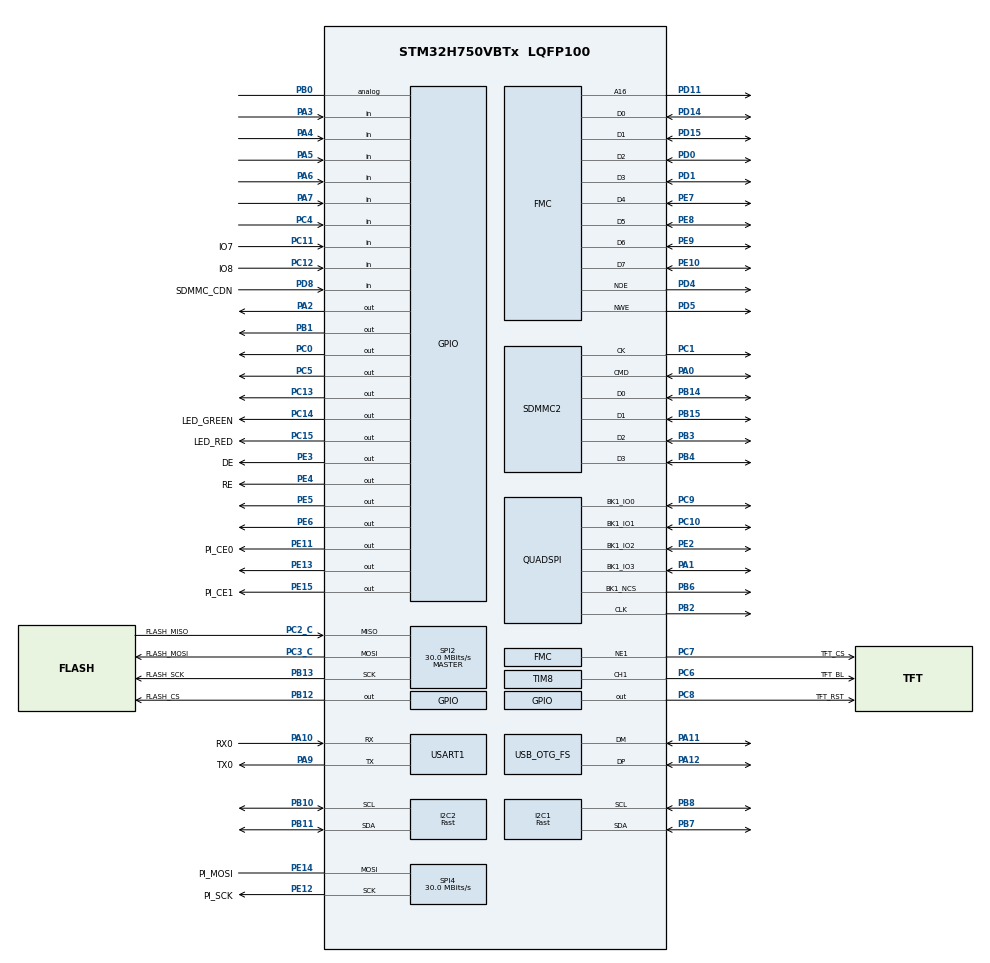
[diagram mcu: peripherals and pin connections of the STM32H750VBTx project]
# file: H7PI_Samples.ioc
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CORTEX_M7.AccessPermission-Cortex_Memory_Protection_Unit_Region0_Settings=MPU_REGION_FULL_ACCESS
CORTEX_M7.AccessPermission-Cortex_Memory_Protection_Unit_Region1_Settings=MPU_REGION_FULL_ACCESS
CORTEX_M7.AccessPermission-Cortex_Memory_Protection_Unit_Region2_Settings=MPU_REGION_FULL_ACCESS
CORTEX_M7.AccessPermission-Cortex_Memory_Protection_Unit_Region3_Settings=MPU_REGION_FULL_ACCESS
CORTEX_M7.AccessPermission-Cortex_Memory_Protection_Unit_Region4_Settings=MPU_REGION_FULL_ACCESS
CORTEX_M7.BaseAddress-Cortex_Memory_Protection_Unit_Region0_Settings=0x60000000
CORTEX_M7.BaseAddress-Cortex_Memory_Protection_Unit_Region1_Settings=0x24000000
CORTEX_M7.BaseAddress-Cortex_Memory_Protection_Unit_Region2_Settings=0x30000000
CORTEX_M7.BaseAddress-Cortex_Memory_Protection_Unit_Region3_Settings=0x38000000
CORTEX_M7.BaseAddress-Cortex_Memory_Protection_Unit_Region4_Settings=0x20000000
CORTEX_M7.CPU_DCache=Enabled
CORTEX_M7.CPU_ICache=Enabled
CORTEX_M7.Enable-Cortex_Memory_Protection_Unit_Region0_Settings=MPU_REGION_ENABLE
CORTEX_M7.Enable-Cortex_Memory_Protection_Unit_Region1_Settings=MPU_REGION_ENABLE
CORTEX_M7.Enable-Cortex_Memory_Protection_Unit_Region2_Settings=MPU_REGION_ENABLE
CORTEX_M7.Enable-Cortex_Memory_Protection_Unit_Region3_Settings=MPU_REGION_ENABLE
CORTEX_M7.Enable-Cortex_Memory_Protection_Unit_Region4_Settings=MPU_REGION_ENABLE
CORTEX_M7.IsBufferable-Cortex_Memory_Protection_Unit_Region0_Settings=MPU_ACCESS_BUFFERABLE
CORTEX_M7.IsBufferable-Cortex_Memory_Protection_Unit_Region1_Settings=MPU_ACCESS_BUFFERABLE
CORTEX_M7.IsBufferable-Cortex_Memory_Protection_Unit_Region2_Settings=MPU_ACCESS_BUFFERABLE
CORTEX_M7.IsBufferable-Cortex_Memory_Protection_Unit_Region3_Settings=MPU_ACCESS_BUFFERABLE
CORTEX_M7.IsBufferable-Cortex_Memory_Protection_Unit_Region4_Settings=MPU_ACCESS_BUFFERABLE
CORTEX_M7.IsCacheable-Cortex_Memory_Protection_Unit_Region1_Settings=MPU_ACCESS_CACHEABLE
CORTEX_M7.IsCacheable-Cortex_Memory_Protection_Unit_Region2_Settings=MPU_ACCESS_CACHEABLE
CORTEX_M7.IsCacheable-Cortex_Memory_Protection_Unit_Region3_Settings=MPU_ACCESS_CACHEABLE
CORTEX_M7.IsCacheable-Cortex_Memory_Protection_Unit_Region4_Settings=MPU_ACCESS_CACHEABLE
CORTEX_M7.IsShareable-Cortex_Memory_Protection_Unit_Region0_Settings=MPU_ACCESS_SHAREABLE
CORTEX_M7.IsShareable-Cortex_Memory_Protection_Unit_Region1_Settings=MPU_ACCESS_SHAREABLE
CORTEX_M7.IsShareable-Cortex_Memory_Protection_Unit_Region2_Settings=MPU_ACCESS_SHAREABLE
CORTEX_M7.IsShareable-Cortex_Memory_Protection_Unit_Region3_Settings=MPU_ACCESS_SHAREABLE
CORTEX_M7.IsShareable-Cortex_Memory_Protection_Unit_Region4_Settings=MPU_ACCESS_SHAREABLE
CORTEX_M7.MPU_Control=MPU_HFNMI_PRIVDEF
CORTEX_M7.Size-Cortex_Memory_Protection_Unit_Region0_Settings=MPU_REGION_SIZE_256KB
CORTEX_M7.Size-Cortex_Memory_Protection_Unit_Region1_Settings=MPU_REGION_SIZE_512KB
CORTEX_M7.Size-Cortex_Memory_Protection_Unit_Region2_Settings=MPU_REGION_SIZE_512KB
CORTEX_M7.Size-Cortex_Memory_Protection_Unit_Region3_Settings=MPU_REGION_SIZE_64KB
CORTEX_M7.Size-Cortex_Memory_Protection_Unit_Region4_Settings=MPU_REGION_SIZE_128KB
CORTEX_M7.TypeExtField-Cortex_Memory_Protection_Unit_Region1_Settings=MPU_TEX_LEVEL1
CORTEX_M7.TypeExtField-Cortex_Memory_Protection_Unit_Region2_Settings=MPU_TEX_LEVEL1
CORTEX_M7.TypeExtField-Cortex_Memory_Protection_Unit_Region3_Settings=MPU_TEX_LEVEL1
CORTEX_M7.TypeExtField-Cortex_Memory_Protection_Unit_Region4_Settings=MPU_TEX_LEVEL1
Dma.Request0=USART1_RX
Dma.Request1=USART1_TX
Dma.USART1_RX.0.Direction=DMA_PERIPH_TO_MEMORY
Dma.USART1_RX.0.EventEnable=DISABLE
Dma.USART1_RX.0.FIFOMode=DMA_FIFOMODE_ENABLE
Dma.USART1_RX.0.FIFOThreshold=DMA_FIFO_THRESHOLD_FULL
Dma.USART1_RX.0.Instance=DMA1_Stream0
Dma.USART1_RX.0.MemBurst=DMA_MBURST_SINGLE
Dma.USART1_RX.0.MemDataAlignment=DMA_MDATAALIGN_BYTE
Dma.USART1_RX.0.MemInc=DMA_MINC_ENABLE
Dma.USART1_RX.0.Mode=DMA_CIRCULAR
Dma.USART1_RX.0.PeriphBurst=DMA_PBURST_SINGLE
Dma.USART1_RX.0.PeriphDataAlignment=DMA_PDATAALIGN_BYTE
Dma.USART1_RX.0.PeriphInc=DMA_PINC_DISABLE
Dma.USART1_RX.0.Polarity=HAL_DMAMUX_REQ_GEN_RISING
Dma.USART1_RX.0.Priority=DMA_PRIORITY_LOW
Dma.USART1_RX.0.RequestNumber=1
Dma.USART1_RX.0.SignalID=NONE
Dma.USART1_RX.0.SyncEnable=DISABLE
Dma.USART1_RX.0.SyncPolarity=HAL_DMAMUX_SYNC_NO_EVENT
Dma.USART1_RX.0.SyncRequestNumber=1
Dma.USART1_RX.0.SyncSignalID=NONE
Dma.USART1_TX.1.Direction=DMA_MEMORY_TO_PERIPH
Dma.USART1_TX.1.EventEnable=DISABLE
Dma.USART1_TX.1.FIFOMode=DMA_FIFOMODE_DISABLE
Dma.USART1_TX.1.Instance=DMA1_Stream1
Dma.USART1_TX.1.MemDataAlignment=DMA_MDATAALIGN_BYTE
Dma.USART1_TX.1.MemInc=DMA_MINC_ENABLE
Dma.USART1_TX.1.Mode=DMA_NORMAL
Dma.USART1_TX.1.PeriphDataAlignment=DMA_PDATAALIGN_BYTE
Dma.USART1_TX.1.PeriphInc=DMA_PINC_DISABLE
Dma.USART1_TX.1.Polarity=HAL_DMAMUX_REQ_GEN_RISING
Dma.USART1_TX.1.Priority=DMA_PRIORITY_LOW
Dma.USART1_TX.1.RequestNumber=1
Dma.USART1_TX.1.SignalID=NONE
Dma.USART1_TX.1.SyncEnable=DISABLE
Dma.USART1_TX.1.SyncPolarity=HAL_DMAMUX_SYNC_NO_EVENT
Dma.USART1_TX.1.SyncRequestNumber=1
Dma.USART1_TX.1.SyncSignalID=NONE
FMC.AddressSetupTime1=1
FMC.BusTurnAroundDuration1=1
FMC.DataSetupTime1=20
FMC.ExtendedMode1=FMC_EXTENDED_MODE_DISABLE
I2C1.I2C_Speed_Mode=I2C_Fast
I2C1.Timing=0x10B040DC
I2C2.I2C_Speed_Mode=I2C_Fast
I2C2.Timing=0x10B040DC
Mcu.Family=STM32H7
Mcu.Name=STM32H750VBTx
Mcu.Package=LQFP100
Mcu.UserConstants=ENABLE_SD_DMA_CACHE_MAINTENANCE,1
NVIC.DMA1_Stream0_IRQn=true\:5\:0\:true\:false\:true\:false\:true
NVIC.DMA1_Stream1_IRQn=true\:5\:0\:true\:false\:true\:false\:true
NVIC.I2C1_EV_IRQn=true\:5\:0\:true\:false\:true\:true\:true
NVIC.I2C2_EV_IRQn=true\:5\:0\:true\:false\:true\:true\:true
NVIC.OTG_FS_IRQn=true\:6\:0\:true\:false\:true\:true\:true
NVIC.PriorityGroup=NVIC_PRIORITYGROUP_4
NVIC.QUADSPI_IRQn=true\:5\:0\:true\:false\:true\:true\:true
NVIC.SDMMC2_IRQn=true\:5\:0\:true\:false\:true\:true\:true
NVIC.USART1_IRQn=true\:5\:0\:true\:false\:true\:true\:true
PA0.GPIO_PuPd=GPIO_NOPULL
PA0.Mode=SD_4_bits_Wide_bus
PA0.Signal=SDMMC2_CMD
PA1.GPIO_Speed=GPIO_SPEED_FREQ_VERY_HIGH
PA1.Mode=Single Bank 1
PA1.Signal=QUADSPI_BK1_IO3
PA10.GPIO_Label=RX0
PA10.GPIO_Speed=GPIO_SPEED_FREQ_VERY_HIGH
PA10.Mode=Asynchronous
PA10.Signal=USART1_RX
PA11.GPIO_Speed=GPIO_SPEED_FREQ_VERY_HIGH
PA11.Mode=Device_Only
PA11.Signal=USB_OTG_FS_DM
PA12.GPIO_PuPd=GPIO_NOPULL
PA12.GPIO_Speed=GPIO_SPEED_FREQ_VERY_HIGH
PA12.Mode=Device_Only
PA12.Signal=USB_OTG_FS_DP
PA13\ (JTMS/SWDIO).Mode=Serial_Wire
PA13\ (JTMS/SWDIO).Signal=DEBUG_JTMS-SWDIO
PA14\ (JTCK/SWCLK).Mode=Serial_Wire
PA14\ (JTCK/SWCLK).Signal=DEBUG_JTCK-SWCLK
PA2.GPIO_PuPd=GPIO_PULLDOWN
PA2.Signal=GPIO_Output
PA3.Signal=GPIO_Input
PA4.GPIO_PuPd=GPIO_PULLUP
PA4.Signal=GPIO_Input
PA5.GPIO_PuPd=GPIO_PULLUP
PA5.Signal=GPIO_Input
PA6.GPIO_PuPd=GPIO_PULLUP
PA6.Signal=GPIO_Input
PA7.GPIO_PuPd=GPIO_PULLUP
PA7.Signal=GPIO_Input
PA9.GPIO_Label=TX0
PA9.GPIO_Speed=GPIO_SPEED_FREQ_VERY_HIGH
PA9.Mode=Asynchronous
PA9.Signal=USART1_TX
PB0.Signal=GPIO_Analog
PB1.Signal=GPIO_Output
PB10.GPIO_PuPd=GPIO_PULLUP
PB10.GPIO_Speed=GPIO_SPEED_FREQ_VERY_HIGH
PB10.Mode=I2C
PB10.Signal=I2C2_SCL
PB11.GPIO_PuPd=GPIO_PULLUP
PB11.GPIO_Speed=GPIO_SPEED_FREQ_VERY_HIGH
PB11.Mode=I2C
PB11.Signal=I2C2_SDA
PB12.GPIO_Label=FLASH_CS
PB12.Signal=GPIO_Output
PB13.GPIO_Label=FLASH_SCK
PB13.GPIO_Speed=GPIO_SPEED_FREQ_VERY_HIGH
PB13.Mode=Full_Duplex_Master
PB13.Signal=SPI2_SCK
PB14.GPIO_PuPd=GPIO_NOPULL
PB14.Mode=SD_4_bits_Wide_bus
PB14.Signal=SDMMC2_D0
PB15.GPIO_PuPd=GPIO_NOPULL
PB15.Mode=SD_4_bits_Wide_bus
PB15.Signal=SDMMC2_D1
PB2.GPIO_Speed=GPIO_SPEED_FREQ_VERY_HIGH
PB2.Mode=Single Bank 1
PB2.Signal=QUADSPI_CLK
PB3\ (JTDO/TRACESWO).GPIO_PuPd=GPIO_NOPULL
PB3\ (JTDO/TRACESWO).Mode=SD_4_bits_Wide_bus
PB3\ (JTDO/TRACESWO).Signal=SDMMC2_D2
PB4\ (NJTRST).GPIO_PuPd=GPIO_NOPULL
PB4\ (NJTRST).Mode=SD_4_bits_Wide_bus
PB4\ (NJTRST).Signal=SDMMC2_D3
PB6.GPIO_PuPd=GPIO_PULLUP
PB6.GPIO_Speed=GPIO_SPEED_FREQ_VERY_HIGH
PB6.Mode=Single Bank 1
PB6.Signal=QUADSPI_BK1_NCS
PB7.GPIO_FM7=SYSCFG_PMCR_I2C_PB7_FMP
PB7.GPIO_PuPd=GPIO_PULLUP
PB7.GPIO_Speed=GPIO_SPEED_FREQ_VERY_HIGH
PB7.Mode=I2C
PB7.Signal=I2C1_SDA
PB8.GPIO_FM8=SYSCFG_PMCR_I2C_PB8_FMP
PB8.GPIO_PuPd=GPIO_PULLUP
PB8.GPIO_Speed=GPIO_SPEED_FREQ_VERY_HIGH
PB8.Mode=I2C
PB8.Signal=I2C1_SCL
PC0.Signal=GPIO_Output
PC1.GPIO_PuPd=GPIO_NOPULL
PC1.Mode=SD_4_bits_Wide_bus
PC1.Signal=SDMMC2_CK
PC10.GPIO_Speed=GPIO_SPEED_FREQ_VERY_HIGH
PC10.Mode=Single Bank 1
PC10.Signal=QUADSPI_BK1_IO1
PC11.GPIO_Label=IO7
PC11.GPIO_PuPd=GPIO_PULLUP
PC11.Signal=GPIO_Input
PC12.GPIO_Label=IO8
PC12.GPIO_PuPd=GPIO_PULLUP
PC12.Signal=GPIO_Input
PC13.Signal=GPIO_Output
PC14-OSC32_IN\ (OSC32_IN).GPIO_Label=LED_GREEN
PC14-OSC32_IN\ (OSC32_IN).Signal=GPIO_Output
PC15-OSC32_OUT\ (OSC32_OUT).GPIO_Label=LED_RED
PC15-OSC32_OUT\ (OSC32_OUT).Signal=GPIO_Output
PC2_C.GPIO_Label=FLASH_MISO
PC2_C.GPIO_Speed=GPIO_SPEED_FREQ_VERY_HIGH
PC2_C.Mode=Full_Duplex_Master
PC2_C.Signal=SPI2_MISO
PC3_C.GPIO_Label=FLASH_MOSI
PC3_C.GPIO_Speed=GPIO_SPEED_FREQ_VERY_HIGH
PC3_C.Mode=Full_Duplex_Master
PC3_C.Signal=SPI2_MOSI
PC4.GPIO_PuPd=GPIO_PULLUP
PC4.Signal=GPIO_Input
PC5.Signal=GPIO_Output
PC6.GPIO_Label=TFT_BL
PC6.Signal=S_TIM8_CH1
PC7.GPIO_Label=TFT_CS
PC7.GPIO_PuPd=GPIO_PULLUP
PC7.Mode=NorPsramChipSelect1_1
PC7.Signal=FMC_NE1
PC8.GPIO_Label=TFT_RST
PC8.Signal=GPIO_Output
PC9.GPIO_PuPd=GPIO_NOPULL
PC9.GPIO_Speed=GPIO_SPEED_FREQ_VERY_HIGH
PC9.Mode=Single Bank 1
PC9.Signal=QUADSPI_BK1_IO0
PD0.Signal=FMC_D2_DA2
PD1.Signal=FMC_D3_DA3
PD11.Signal=FMC_A16_CLE
PD12.Signal=S_TIM4_CH1
PD14.Signal=FMC_D0_DA0
PD15.Signal=FMC_D1_DA1
PD4.GPIO_PuPd=GPIO_PULLUP
PD4.Signal=FMC_NOE
PD5.GPIO_PuPd=GPIO_PULLUP
PD5.Signal=FMC_NWE
PD8.GPIO_Label=SDMMC_CDN
PD8.Signal=GPIO_Input
PE0.GPIO_Label=RX1
PE0.Signal=UART8_RX
PE1.GPIO_Label=TX1
PE1.Signal=UART8_TX
PE10.Signal=FMC_D7_DA7
PE11.GPIO_Label=PI_CE0
PE11.Signal=GPIO_Output
PE12.GPIO_Label=PI_SCK
PE12.GPIO_Speed=GPIO_SPEED_FREQ_VERY_HIGH
PE12.Mode=Simplex_Bidirectional_Master
PE12.Signal=SPI4_SCK
PE13.GPIO_PuPd=GPIO_PULLDOWN
PE13.Signal=GPIO_Output
PE14.GPIO_Label=PI_MOSI
PE14.GPIO_Speed=GPIO_SPEED_FREQ_VERY_HIGH
PE14.Mode=Simplex_Bidirectional_Master
PE14.Signal=SPI4_MOSI
PE15.GPIO_Label=PI_CE1
PE15.Signal=GPIO_Output
PE2.GPIO_Speed=GPIO_SPEED_FREQ_VERY_HIGH
PE2.Mode=Single Bank 1
PE2.Signal=QUADSPI_BK1_IO2
PE3.GPIO_Label=DE
PE3.Signal=GPIO_Output
PE4.GPIO_Label=RE
PE4.Signal=GPIO_Output
PE5.Signal=GPIO_Output
PE6.Signal=GPIO_Output
PE7.Signal=FMC_D4_DA4
PE8.Signal=FMC_D5_DA5
PE9.Signal=FMC_D6_DA6
PH0-OSC_IN\ (PH0).Signal=RCC_OSC_IN
PH1-OSC_OUT\ (PH1).Signal=RCC_OSC_OUT
ProjectManager.HeapSize=0x30000
ProjectManager.StackSize=0x30000
ProjectManager.TargetToolchain=MDK-ARM V5
QUADSPI.ClockPrescaler=2
QUADSPI.FifoThreshold=4
QUADSPI.FlashSize=22
QUADSPI.SampleShifting=QSPI_SAMPLE_SHIFTING_HALFCYCLE
RCC.ADCFreq_Value=240000000
RCC.APB1Freq_Value=60000000
RCC.APB2Freq_Value=60000000
RCC.APB3Freq_Value=60000000
RCC.APB4Freq_Value=60000000
RCC.CortexFreq_Value=240000000
RCC.D1CPRE=RCC_SYSCLK_DIV2
RCC.D1PPRE=RCC_APB3_DIV2
RCC.D2PPRE1=RCC_APB1_DIV2
RCC.D2PPRE2=RCC_APB2_DIV2
RCC.D3PPRE=RCC_APB4_DIV2
RCC.DIVM1=4
RCC.DIVM2=4
RCC.DIVM3=4
RCC.DIVN1=60
RCC.DIVN2=15
RCC.DIVN3=15
RCC.DIVP2=1
RCC.DIVP3=1
RCC.DIVQ1=4
RCC.DIVQ2=1
RCC.DIVQ3=1
RCC.DIVR1=4
RCC.DIVR2=1
RCC.DIVR3=1
RCC.FMCCLockSelection=RCC_FMCCLKSOURCE_PLL
RCC.HCLKFreq_Value=120000000
RCC.HPRE=RCC_HCLK_DIV2
RCC.I2C123CLockSelection=RCC_I2C123CLKSOURCE_PLL3
RCC.PLL2FRACN=0
RCC.PLL3FRACN=0
RCC.PLLFRACN=0
RCC.QSPICLockSelection=RCC_QSPICLKSOURCE_PLL2
RCC.SYSCLKFreq_VALUE=480000000
RCC.SYSCLKSource=RCC_SYSCLKSOURCE_PLLCLK
RCC.Spi45ClockSelection=RCC_SPI45CLKSOURCE_PLL2
RCC.SupplySource=PWR_EXTERNAL_SOURCE_SUPPLY
RCC.USART16CLockSelection=RCC_USART16CLKSOURCE_PLL2
RCC.USBCLockSelection=RCC_USBCLKSOURCE_HSI48
RCC.USBFreq_Value=48000000
RCC.VDD_VALUE=3.2
SDMMC2.ClockDiv=79
SDMMC2.HardwareFlowControl=SDMMC_HARDWARE_FLOW_CONTROL_DISABLE
SH.FMC_A16_CLE.0=FMC_A16,A16_1
SH.FMC_D0_DA0.0=FMC_D0,8b-d1
SH.FMC_D1_DA1.0=FMC_D1,8b-d1
SH.FMC_D2_DA2.0=FMC_D2,8b-d1
SH.FMC_D3_DA3.0=FMC_D3,8b-d1
SH.FMC_D4_DA4.0=FMC_D4,8b-d1
SH.FMC_D5_DA5.0=FMC_D5,8b-d1
SH.FMC_D6_DA6.0=FMC_D6,8b-d1
SH.FMC_D7_DA7.0=FMC_D7,8b-d1
SH.FMC_NOE.0=FMC_NOE,Lcd1
SH.FMC_NWE.0=FMC_NWE,Lcd1
SH.S_TIM4_CH1.0=TIM4_CH1
SH.S_TIM8_CH1.0=TIM8_CH1,PWM Generation1 CH1
SPI2.BaudRatePrescaler=SPI_BAUDRATEPRESCALER_8
SPI2.CLKPhase=SPI_PHASE_2EDGE
SPI2.CLKPolarity=SPI_POLARITY_HIGH
SPI2.CalculateBaudRate=30.0 MBits/s
SPI2.DataSize=SPI_DATASIZE_8BIT
SPI2.Direction=SPI_DIRECTION_2LINES
SPI2.MasterKeepIOState=SPI_MASTER_KEEP_IO_STATE_ENABLE
SPI2.MasterSSIdleness=SPI_MASTER_SS_IDLENESS_00CYCLE
SPI2.Mode=SPI_MODE_MASTER
SPI2.NSSPMode=SPI_NSS_PULSE_DISABLE
SPI2.VirtualType=VM_MASTER
SPI4.BaudRatePrescaler=SPI_BAUDRATEPRESCALER_8
SPI4.CLKPhase=SPI_PHASE_1EDGE
SPI4.CalculateBaudRate=30.0 MBits/s
SPI4.DataSize=SPI_DATASIZE_8BIT
SPI4.Direction=SPI_DIRECTION_1LINE
SPI4.FifoThreshold=SPI_FIFO_THRESHOLD_01DATA
SPI4.Mode=SPI_MODE_MASTER
SPI4.NSSPMode=SPI_NSS_PULSE_DISABLE
SPI4.VirtualType=VM_MASTER
TIM8.AutoReloadPreload=TIM_AUTORELOAD_PRELOAD_ENABLE
TIM8.Channel-PWM\ Generation1\ CH1=TIM_CHANNEL_1
TIM8.OCPolarity_1=TIM_OCPOLARITY_LOW
TIM8.Period=239
TIM8.Prescaler=0
TIM8.Pulse-PWM\ Generation1\ CH1=499
USART1.FIFOMode=FIFOMODE_ENABLE
USART1.RXFIFOThreshold=RXFIFO_THRESHOLD_FULL
USART1.TXFIFOThreshold=TXFIFO_THRESHOLD_EMPTY
USART1.VirtualMode-Asynchronous=VM_ASYNC
USB_OTG_FS.VirtualMode=Device_Only
VP_CRC_VS_CRC.Mode=CRC_Activate
board=custom

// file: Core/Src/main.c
/* USER CODE BEGIN Header */
/**
  ******************************************************************************
  * @file           : main.c
  * @brief          : Main program body
  ******************************************************************************
  * @attention
  *
  * <h2><center>&copy; Copyright (c) 2020 STMicroelectronics.
  * All rights reserved.</center></h2>
  *
  * This software component is licensed by ST under Ultimate Liberty license
  * SLA0044, the "License"; You may not use this file except in compliance with
  * the License. You may obtain a copy of the License at:
  *                             www.st.com/SLA0044
  *
  ******************************************************************************
  */
/* USER CODE END Header */

#include "main.h"
#include "crc.h"
#include "dma.h"
#include "i2c.h"
#include "quadspi.h"
#include "sdmmc.h"
#include "spi.h"
#include "tim.h"
#include "usart.h"
#include "usb_otg.h"
#include "gpio.h"
#include "fmc.h"

void SystemClock_Config(void);
static void MPU_Config(void);

int main(void)
{
  /* USER CODE BEGIN 1 */
	__enable_irq();
  /* USER CODE END 1 */

  /* MPU Configuration--------------------------------------------------------*/
  MPU_Config();

  /* Enable I-Cache---------------------------------------------------------*/
  SCB_EnableICache();

  /* Enable D-Cache---------------------------------------------------------*/
  SCB_EnableDCache();

  /* MCU Configuration--------------------------------------------------------*/

  /* Reset of all peripherals, Initializes the Flash interface and the Systick. */
  HAL_Init();

  /* Configure the system clock */
  SystemClock_Config();

  /* Initialize all configured peripherals */
  MX_GPIO_Init();
  MX_DMA_Init();
  MX_FMC_Init();
  MX_TIM8_Init();
  MX_CRC_Init();
  MX_SDMMC2_SD_Init();
  MX_USART1_UART_Init();
  MX_I2C2_Init();
  MX_SPI2_Init();
  MX_SPI4_Init();
  MX_I2C1_Init();
  /* USER CODE BEGIN 2 */
	void sys_OsStart(void);
  sys_OsStart();
  /* USER CODE END 2 */

  /* Infinite loop */
  while (1)
  {

  }
}

void SystemClock_Config(void)
{
  RCC_OscInitTypeDef RCC_OscInitStruct = {0};
  RCC_ClkInitTypeDef RCC_ClkInitStruct = {0};
  RCC_PeriphCLKInitTypeDef PeriphClkInitStruct = {0};

  /** Supply configuration update enable
  */
  HAL_PWREx_ConfigSupply(PWR_EXTERNAL_SOURCE_SUPPLY);
  /** Configure the main internal regulator output voltage
  */
  __HAL_PWR_VOLTAGESCALING_CONFIG(PWR_REGULATOR_VOLTAGE_SCALE0);

  while(!__HAL_PWR_GET_FLAG(PWR_FLAG_VOSRDY)) {}
  /** Macro to configure the PLL clock source
  */
  __HAL_RCC_PLL_PLLSOURCE_CONFIG(RCC_PLLSOURCE_HSI);
  /** Initializes the CPU, AHB and APB busses clocks
  */
  RCC_OscInitStruct.OscillatorType = RCC_OSCILLATORTYPE_HSI48|RCC_OSCILLATORTYPE_HSI;
  RCC_OscInitStruct.HSIState = RCC_HSI_DIV1;
  RCC_OscInitStruct.HSICalibrationValue = RCC_HSICALIBRATION_DEFAULT;
  RCC_OscInitStruct.HSI48State = RCC_HSI48_ON;
  RCC_OscInitStruct.PLL.PLLState = RCC_PLL_ON;
  RCC_OscInitStruct.PLL.PLLSource = RCC_PLLSOURCE_HSI;
  RCC_OscInitStruct.PLL.PLLM = 4;
  RCC_OscInitStruct.PLL.PLLN = 60;
  RCC_OscInitStruct.PLL.PLLP = 2;
  RCC_OscInitStruct.PLL.PLLQ = 4;
  RCC_OscInitStruct.PLL.PLLR = 4;
  RCC_OscInitStruct.PLL.PLLRGE = RCC_PLL1VCIRANGE_3;
  RCC_OscInitStruct.PLL.PLLVCOSEL = RCC_PLL1VCOWIDE;
  RCC_OscInitStruct.PLL.PLLFRACN = 0;
  if (HAL_RCC_OscConfig(&RCC_OscInitStruct) != HAL_OK)
  {
    Error_Handler();
  }
  /** Initializes the CPU, AHB and APB busses clocks
  */
  RCC_ClkInitStruct.ClockType = RCC_CLOCKTYPE_HCLK|RCC_CLOCKTYPE_SYSCLK
                              |RCC_CLOCKTYPE_PCLK1|RCC_CLOCKTYPE_PCLK2
                              |RCC_CLOCKTYPE_D3PCLK1|RCC_CLOCKTYPE_D1PCLK1;
  RCC_ClkInitStruct.SYSCLKSource = RCC_SYSCLKSOURCE_PLLCLK;
  RCC_ClkInitStruct.SYSCLKDivider = RCC_SYSCLK_DIV2;
  RCC_ClkInitStruct.AHBCLKDivider = RCC_HCLK_DIV2;
  RCC_ClkInitStruct.APB3CLKDivider = RCC_APB3_DIV2;
  RCC_ClkInitStruct.APB1CLKDivider = RCC_APB1_DIV2;
  RCC_ClkInitStruct.APB2CLKDivider = RCC_APB2_DIV2;
  RCC_ClkInitStruct.APB4CLKDivider = RCC_APB4_DIV2;

  if (HAL_RCC_ClockConfig(&RCC_ClkInitStruct, FLASH_LATENCY_1) != HAL_OK)
  {
    Error_Handler();
  }
  PeriphClkInitStruct.PeriphClockSelection = RCC_PERIPHCLK_USART1|RCC_PERIPHCLK_SPI4
                              |RCC_PERIPHCLK_SPI2|RCC_PERIPHCLK_SDMMC
                              |RCC_PERIPHCLK_I2C2|RCC_PERIPHCLK_I2C1
                              |RCC_PERIPHCLK_USB|RCC_PERIPHCLK_QSPI
                              |RCC_PERIPHCLK_FMC;
  PeriphClkInitStruct.PLL2.PLL2M = 4;
  PeriphClkInitStruct.PLL2.PLL2N = 15;
  PeriphClkInitStruct.PLL2.PLL2P = 1;
  PeriphClkInitStruct.PLL2.PLL2Q = 1;
  PeriphClkInitStruct.PLL2.PLL2R = 1;
  PeriphClkInitStruct.PLL2.PLL2RGE = RCC_PLL2VCIRANGE_3;
  PeriphClkInitStruct.PLL2.PLL2VCOSEL = RCC_PLL2VCOWIDE;
  PeriphClkInitStruct.PLL2.PLL2FRACN = 0;
  PeriphClkInitStruct.PLL3.PLL3M = 4;
  PeriphClkInitStruct.PLL3.PLL3N = 15;
  PeriphClkInitStruct.PLL3.PLL3P = 1;
  PeriphClkInitStruct.PLL3.PLL3Q = 1;
  PeriphClkInitStruct.PLL3.PLL3R = 1;
  PeriphClkInitStruct.PLL3.PLL3RGE = RCC_PLL3VCIRANGE_3;
  PeriphClkInitStruct.PLL3.PLL3VCOSEL = RCC_PLL3VCOWIDE;
  PeriphClkInitStruct.PLL3.PLL3FRACN = 0;
  PeriphClkInitStruct.FmcClockSelection = RCC_FMCCLKSOURCE_PLL;
  PeriphClkInitStruct.QspiClockSelection = RCC_QSPICLKSOURCE_PLL2;
  PeriphClkInitStruct.SdmmcClockSelection = RCC_SDMMCCLKSOURCE_PLL;
  PeriphClkInitStruct.Spi123ClockSelection = RCC_SPI123CLKSOURCE_PLL;
  PeriphClkInitStruct.Spi45ClockSelection = RCC_SPI45CLKSOURCE_PLL2;
  PeriphClkInitStruct.Usart16ClockSelection = RCC_USART16CLKSOURCE_PLL2;
  PeriphClkInitStruct.I2c123ClockSelection = RCC_I2C123CLKSOURCE_PLL3;
  PeriphClkInitStruct.UsbClockSelection = RCC_USBCLKSOURCE_HSI48;
  if (HAL_RCCEx_PeriphCLKConfig(&PeriphClkInitStruct) != HAL_OK)
  {
    Error_Handler();
  }
  /** Enable USB Voltage detector
  */
  HAL_PWREx_EnableUSBVoltageDetector();
}

/* MPU Configuration */

void MPU_Config(void)
{
  MPU_Region_InitTypeDef MPU_InitStruct = {0};

  /* Disables the MPU */
  HAL_MPU_Disable();
  /** Initializes and configures the Region and the memory to be protected
  */
  MPU_InitStruct.Enable = MPU_REGION_ENABLE;
  MPU_InitStruct.Number = MPU_REGION_NUMBER0;
  MPU_InitStruct.BaseAddress = 0x60000000;
  MPU_InitStruct.Size = MPU_REGION_SIZE_256KB;
  MPU_InitStruct.SubRegionDisable = 0x0;
  MPU_InitStruct.TypeExtField = MPU_TEX_LEVEL0;
  MPU_InitStruct.AccessPermission = MPU_REGION_FULL_ACCESS;
  MPU_InitStruct.DisableExec = MPU_INSTRUCTION_ACCESS_ENABLE;
  MPU_InitStruct.IsShareable = MPU_ACCESS_SHAREABLE;
  MPU_InitStruct.IsCacheable = MPU_ACCESS_NOT_CACHEABLE;
  MPU_InitStruct.IsBufferable = MPU_ACCESS_BUFFERABLE;

  HAL_MPU_ConfigRegion(&MPU_InitStruct);
  /** Initializes and configures the Region and the memory to be protected
  */
  MPU_InitStruct.Enable = MPU_REGION_ENABLE;
  MPU_InitStruct.Number = MPU_REGION_NUMBER1;
  MPU_InitStruct.BaseAddress = 0x24000000;
  MPU_InitStruct.Size = MPU_REGION_SIZE_512KB;
  MPU_InitStruct.SubRegionDisable = 0x0;
  MPU_InitStruct.TypeExtField = MPU_TEX_LEVEL1;
  MPU_InitStruct.AccessPermission = MPU_REGION_FULL_ACCESS;
  MPU_InitStruct.DisableExec = MPU_INSTRUCTION_ACCESS_ENABLE;
  MPU_InitStruct.IsShareable = MPU_ACCESS_SHAREABLE;
  MPU_InitStruct.IsCacheable = MPU_ACCESS_CACHEABLE;
  MPU_InitStruct.IsBufferable = MPU_ACCESS_BUFFERABLE;

  HAL_MPU_ConfigRegion(&MPU_InitStruct);
  /** Initializes and configures the Region and the memory to be protected
  */
  MPU_InitStruct.Enable = MPU_REGION_ENABLE;
  MPU_InitStruct.Number = MPU_REGION_NUMBER2;
  MPU_InitStruct.BaseAddress = 0x30000000;
  MPU_InitStruct.Size = MPU_REGION_SIZE_512KB;
  MPU_InitStruct.SubRegionDisable = 0x0;
  MPU_InitStruct.TypeExtField = MPU_TEX_LEVEL1;
  MPU_InitStruct.AccessPermission = MPU_REGION_FULL_ACCESS;
  MPU_InitStruct.DisableExec = MPU_INSTRUCTION_ACCESS_ENABLE;
  MPU_InitStruct.IsShareable = MPU_ACCESS_SHAREABLE;
  MPU_InitStruct.IsCacheable = MPU_ACCESS_CACHEABLE;
  MPU_InitStruct.IsBufferable = MPU_ACCESS_BUFFERABLE;

  HAL_MPU_ConfigRegion(&MPU_InitStruct);
  /** Initializes and configures the Region and the memory to be protected
  */
  MPU_InitStruct.Enable = MPU_REGION_ENABLE;
  MPU_InitStruct.Number = MPU_REGION_NUMBER3;
  MPU_InitStruct.BaseAddress = 0x38000000;
  MPU_InitStruct.Size = MPU_REGION_SIZE_64KB;
  MPU_InitStruct.SubRegionDisable = 0x0;
  MPU_InitStruct.TypeExtField = MPU_TEX_LEVEL1;
  MPU_InitStruct.AccessPermission = MPU_REGION_FULL_ACCESS;
  MPU_InitStruct.DisableExec = MPU_INSTRUCTION_ACCESS_ENABLE;
  MPU_InitStruct.IsShareable = MPU_ACCESS_SHAREABLE;
  MPU_InitStruct.IsCacheable = MPU_ACCESS_CACHEABLE;
  MPU_InitStruct.IsBufferable = MPU_ACCESS_BUFFERABLE;

  HAL_MPU_ConfigRegion(&MPU_InitStruct);
  /** Initializes and configures the Region and the memory to be protected
  */
  MPU_InitStruct.Enable = MPU_REGION_ENABLE;
  MPU_InitStruct.Number = MPU_REGION_NUMBER4;
  MPU_InitStruct.BaseAddress = 0x20000000;
  MPU_InitStruct.Size = MPU_REGION_SIZE_128KB;
  MPU_InitStruct.SubRegionDisable = 0x0;
  MPU_InitStruct.TypeExtField = MPU_TEX_LEVEL1;
  MPU_InitStruct.AccessPermission = MPU_REGION_FULL_ACCESS;
  MPU_InitStruct.DisableExec = MPU_INSTRUCTION_ACCESS_ENABLE;
  MPU_InitStruct.IsShareable = MPU_ACCESS_SHAREABLE;
  MPU_InitStruct.IsCacheable = MPU_ACCESS_CACHEABLE;
  MPU_InitStruct.IsBufferable = MPU_ACCESS_BUFFERABLE;

  HAL_MPU_ConfigRegion(&MPU_InitStruct);
  /* Enables the MPU */
  HAL_MPU_Enable(MPU_HFNMI_PRIVDEF);

}

void Error_Handler(void)
{
}

/************************ (C) COPYRIGHT STMicroelectronics *****END OF FILE****/
